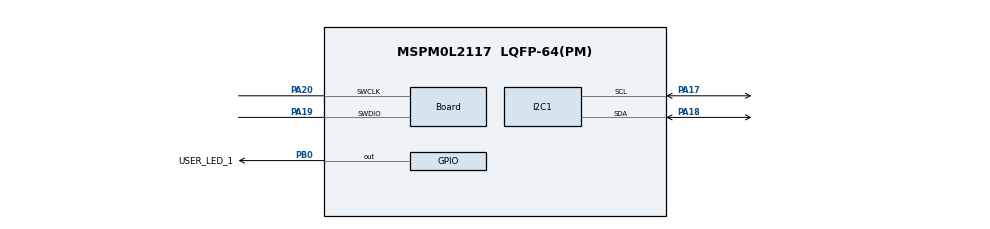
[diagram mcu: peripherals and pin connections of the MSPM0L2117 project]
//@cliArgs --device "MSPM0L211X" --package "LQFP-64(PM)" --part "Default"
//@v2CliArgs --device "MSPM0L2117" --package "LQFP-64(PM)"
// @cliArgs --board /ti/boards/LP_MSPM0L2117 --rtos nortos

/**
 * Import the modules used in this configuration.
 */
const Board = scripting.addModule("/ti/driverlib/Board");
const GPIO  = scripting.addModule("/ti/driverlib/GPIO", {}, false);
const GPIO1 = GPIO.addInstance();
const I2C   = scripting.addModule("/ti/driverlib/I2C", {}, false);
const I2C1  = I2C.addInstance();
const SYSCTL = scripting.addModule("/ti/driverlib/SYSCTL");

/**
 * Write custom configuration values to the imported modules.
 */
Board.peripheral.$assign          = "DEBUGSS";
Board.peripheral.swclkPin.$assign = "PA20";
Board.peripheral.swdioPin.$assign = "PA19";

GPIO1.$name                                 = "GPIO_LEDS";
GPIO1.associatedPins[0].$name               = "USER_LED_1";
GPIO1.associatedPins[0].initialValue        = "CLEARED";
GPIO1.associatedPins[0].pin.$assign         = "PB0";

I2C1.basicControllerBusSpeed   = 400000;
I2C1.advControllerTXFIFOTRIG   = "ALMOST_EMPTY";
I2C1.basicTargetAddress        = 0x48;
I2C1.$name                     = "I2C";
I2C1.basicEnableTarget         = true;
I2C1.peripheral.$assign        = "UC7";
I2C1.peripheral.sdaPin.$assign = "PA18";
I2C1.peripheral.sclPin.$assign = "PA17";

SYSCTL.powerPolicy        = "STOP0";
SYSCTL.peripheral.$assign = "SYSCTL";
SYSCTL.clockTreeEn = true;
SYSCTL.forceDefaultClkConfig = true;
